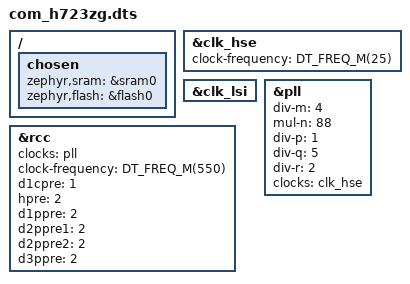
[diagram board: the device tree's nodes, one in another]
/*
 *        Copyright (c) PINGSPACE SDN BHD
 *        Author: Manojkumar <manojkumar.subramaniam@pingspace.co>
 *        SPDX-License-Identifier: Apache-2.0
 *        DTS FOR CUSTOM V1 BOARD (BSP)
 */
/dts-v1/;
#include <st/h7/stm32h723Xg.dtsi>
#include <st/h7/stm32h723zgtx-pinctrl.dtsi>
#include <zephyr/dt-bindings/input/input-event-codes.h>

/ {
	chosen {
		zephyr,sram = &sram0;
		zephyr,flash = &flash0;
	};
};

&clk_hse {
	clock-frequency = <DT_FREQ_M(25)>; /* HSE 25MHz clock */
	status = "okay";
};

&clk_lsi {
	status = "okay";
};

&pll {
	div-m = <4>;
	mul-n = <88>;
	div-p = <1>;
	div-q = <5>;
	div-r = <2>;
	clocks = <&clk_hse>;
	status = "okay";
};

&rcc {
	clocks = <&pll>;
	clock-frequency = <DT_FREQ_M(550)>;
	d1cpre = <1>;
	hpre = <2>;    /* HCLK: 275   MHz */
	d1ppre = <2>;  /* APB1: 137.5 MHz */
	d2ppre1 = <2>; /* APB2: 137.5 MHz */
	d2ppre2 = <2>; /* APB3: 137.5 MHz */
	d3ppre = <2>;  /* APB4: 137.5 MHz */
};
